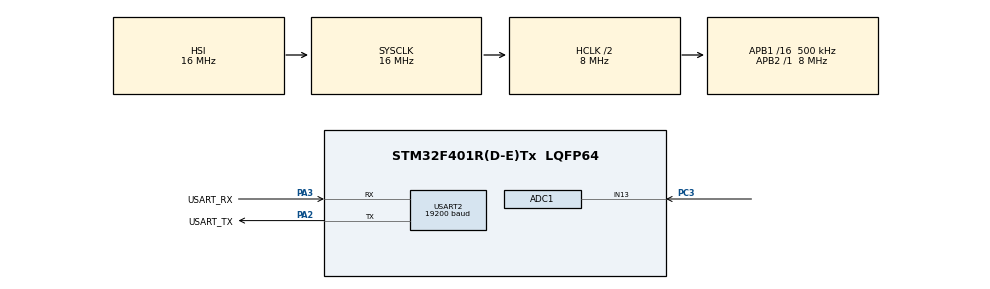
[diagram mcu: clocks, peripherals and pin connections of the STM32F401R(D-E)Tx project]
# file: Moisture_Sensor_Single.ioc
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ADC1.Channel-0\#ChannelRegularConversion=ADC_CHANNEL_13
ADC1.ClockPrescaler=ADC_CLOCK_SYNC_PCLK_DIV8
ADC1.NbrOfConversion=1
ADC1.NbrOfConversionFlag=1
ADC1.Rank-0\#ChannelRegularConversion=1
ADC1.Resolution=ADC_RESOLUTION_12B
ADC1.SamplingTime-0\#ChannelRegularConversion=ADC_SAMPLETIME_3CYCLES
ADC1.master=1
Mcu.Family=STM32F4
Mcu.Name=STM32F401R(D-E)Tx
Mcu.Package=LQFP64
NVIC.PriorityGroup=NVIC_PRIORITYGROUP_0
NVIC.RTC_WKUP_IRQn=true\:0\:0\:false\:false\:true\:true\:true\:true
PA13.GPIO_Label=TMS
PA13.Mode=Serial_Wire
PA13.Signal=SYS_JTMS-SWDIO
PA14.GPIO_Label=TCK
PA14.Mode=Serial_Wire
PA14.Signal=SYS_JTCK-SWCLK
PA2.GPIO_Label=USART_TX
PA2.GPIO_Mode=GPIO_MODE_AF_PP
PA2.GPIO_PuPd=GPIO_NOPULL
PA2.GPIO_Speed=GPIO_SPEED_FREQ_LOW
PA2.Mode=Asynchronous
PA2.Signal=USART2_TX
PA3.GPIO_Label=USART_RX
PA3.GPIO_Mode=GPIO_MODE_AF_PP
PA3.GPIO_PuPd=GPIO_NOPULL
PA3.GPIO_Speed=GPIO_SPEED_FREQ_LOW
PA3.Mode=Asynchronous
PA3.Signal=USART2_RX
PB3.GPIO_Label=SWO
PB3.Signal=SYS_JTDO-SWO
PC14-OSC32_IN.Mode=LSE-External-Oscillator
PC14-OSC32_IN.Signal=RCC_OSC32_IN
PC15-OSC32_OUT.Mode=LSE-External-Oscillator
PC15-OSC32_OUT.Signal=RCC_OSC32_OUT
PC3.Signal=ADCx_IN13
PH0\ -\ OSC_IN.Mode=HSE-External-Clock-Source
PH0\ -\ OSC_IN.Signal=RCC_OSC_IN
PH1\ -\ OSC_OUT.Mode=HSE-External-Clock-Source
PH1\ -\ OSC_OUT.Signal=RCC_OSC_OUT
ProjectManager.HeapSize=0x200
ProjectManager.StackSize=0x400
ProjectManager.TargetToolchain=STM32CubeIDE
RCC.48MHZClocksFreq_Value=18285714.285714287
RCC.AHBCLKDivider=RCC_SYSCLK_DIV2
RCC.AHBFreq_Value=8000000
RCC.APB1CLKDivider=RCC_HCLK_DIV16
RCC.APB1Freq_Value=500000
RCC.APB1TimFreq_Value=1000000
RCC.APB2Freq_Value=8000000
RCC.APB2TimFreq_Value=8000000
RCC.CortexFreq_Value=1000000
RCC.Cortex_Div=SYSTICK_CLKSOURCE_HCLK_DIV8
RCC.HCLKFreq_Value=8000000
RCC.HSE_VALUE=8000000
RCC.HSI_VALUE=16000000
RCC.PLLM=8
RCC.PLLN=64
RCC.PLLQ=7
RCC.RCC_RTC_Clock_Source_FROM_HSE=RCC_RTCCLKSOURCE_HSE_DIV31
RCC.SYSCLKFreq_VALUE=16000000
RCC.VCOOutputFreq_Value=128000000
RTC.WakeUpClock=RTC_WAKEUPCLOCK_CK_SPRE_16BITS
RTC.WakeUpCounter=4
SH.ADCx_IN13.0=ADC1_IN13,IN13
USART2.BaudRate=19200
USART2.VirtualMode=VM_ASYNC
VP_RTC_VS_RTC_Activate.Mode=RTC_Enabled
VP_RTC_VS_RTC_WakeUp_intern.Mode=WakeUp
board=NUCLEO-F401RE

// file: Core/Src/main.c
/* USER CODE BEGIN Header */
/**
  ******************************************************************************
  * @file           : main.c
  * @brief          : Main program body
  ******************************************************************************
  * @attention
  *
  * Copyright (c) 2024 STMicroelectronics.
  * All rights reserved.
  *
  * This software is licensed under terms that can be found in the LICENSE file
  * in the root directory of this software component.
  * If no LICENSE file comes with this software, it is provided AS-IS.
  *
  ******************************************************************************
  */
/* USER CODE END Header */
#include "main.h"

/* USER CODE BEGIN Includes */
#include <stdio.h>
/* USER CODE END Includes */

/* USER CODE BEGIN PD */
#define VREF 3.3
/* USER CODE END PD */

ADC_HandleTypeDef hadc1;

RTC_HandleTypeDef hrtc;

UART_HandleTypeDef huart2;

/* USER CODE BEGIN PV */
uint16_t sensor_reading = 0;
float sensor_reading_processed;
/* USER CODE END PV */

void SystemClock_Config(void);
static void MX_GPIO_Init(void);
static void MX_USART2_UART_Init(void);
static void MX_ADC1_Init(void);
static void MX_RTC_Init(void);
/* USER CODE BEGIN PFP */
int _write(int file, char *data, int len);	//For console printing
/* USER CODE END PFP */

int main(void)
{

  /* MCU Configuration--------------------------------------------------------*/

  /* Reset of all peripherals, Initializes the Flash interface and the Systick. */
  HAL_Init();

  /* Configure the system clock */
  SystemClock_Config();

  /* Initialize all configured peripherals */
  MX_GPIO_Init();
  MX_USART2_UART_Init();
  MX_ADC1_Init();
  MX_RTC_Init();

  /* Infinite loop */
  /* USER CODE BEGIN WHILE */
  while (1)
  {
	// LOW POWER MODE ENTER PROTOCOL
	//printf("Entering LOW POWER\r\n");
	HAL_SuspendTick();
    HAL_PWR_EnterSTOPMode(PWR_LOWPOWERREGULATOR_ON, PWR_STOPENTRY_WFI);
    // LOW POWER MODE EXIT PROTOCOL
	HAL_ResumeTick();
	//printf("Exiting LOW POWER\r\n");

	// SENSOR READING PROTOCOL

	// Start ADC Conversion
	HAL_ADC_Start(&hadc1);  // Start ADC conversion
	// Poll for ADC conversion completion
	if (HAL_ADC_PollForConversion(&hadc1, HAL_MAX_DELAY) == HAL_OK)
	{
		// Read ADC conversion result
		sensor_reading = HAL_ADC_GetValue(&hadc1);

		// Process the ADC value (e.g., convert to voltage or a moisture level)
		sensor_reading_processed = (sensor_reading / 4095.0) * VREF;

		// Print the ADC value and voltage
		printf("ADC Value: %d\r\n", sensor_reading);
		printf("Sensor Voltage: %.2f V\r\n", sensor_reading_processed);

		// You can add more logic to decide whether to water the plants based on the sensor data
	}

	    // Stop ADC to save power
	    HAL_ADC_Stop(&hadc1);
    /* USER CODE END WHILE */

  }
}

void SystemClock_Config(void)
{
  RCC_OscInitTypeDef RCC_OscInitStruct = {0};
  RCC_ClkInitTypeDef RCC_ClkInitStruct = {0};

  /** Configure the main internal regulator output voltage
  */
  __HAL_RCC_PWR_CLK_ENABLE();
  __HAL_PWR_VOLTAGESCALING_CONFIG(PWR_REGULATOR_VOLTAGE_SCALE2);

  /** Initializes the RCC Oscillators according to the specified parameters
  * in the RCC_OscInitTypeDef structure.
  */
  RCC_OscInitStruct.OscillatorType = RCC_OSCILLATORTYPE_HSI|RCC_OSCILLATORTYPE_LSI;
  RCC_OscInitStruct.HSIState = RCC_HSI_ON;
  RCC_OscInitStruct.HSICalibrationValue = RCC_HSICALIBRATION_DEFAULT;
  RCC_OscInitStruct.LSIState = RCC_LSI_ON;
  RCC_OscInitStruct.PLL.PLLState = RCC_PLL_NONE;
  if (HAL_RCC_OscConfig(&RCC_OscInitStruct) != HAL_OK)
  {
    Error_Handler();
  }

  /** Initializes the CPU, AHB and APB buses clocks
  */
  RCC_ClkInitStruct.ClockType = RCC_CLOCKTYPE_HCLK|RCC_CLOCKTYPE_SYSCLK
                              |RCC_CLOCKTYPE_PCLK1|RCC_CLOCKTYPE_PCLK2;
  RCC_ClkInitStruct.SYSCLKSource = RCC_SYSCLKSOURCE_HSI;
  RCC_ClkInitStruct.AHBCLKDivider = RCC_SYSCLK_DIV2;
  RCC_ClkInitStruct.APB1CLKDivider = RCC_HCLK_DIV16;
  RCC_ClkInitStruct.APB2CLKDivider = RCC_HCLK_DIV1;

  if (HAL_RCC_ClockConfig(&RCC_ClkInitStruct, FLASH_LATENCY_0) != HAL_OK)
  {
    Error_Handler();
  }
}

static void MX_ADC1_Init(void)
{

  ADC_ChannelConfTypeDef sConfig = {0};

  /** Configure the global features of the ADC (Clock, Resolution, Data Alignment and number of conversion)
  */
  hadc1.Instance = ADC1;
  hadc1.Init.ClockPrescaler = ADC_CLOCK_SYNC_PCLK_DIV8;
  hadc1.Init.Resolution = ADC_RESOLUTION_12B;
  hadc1.Init.ScanConvMode = DISABLE;
  hadc1.Init.ContinuousConvMode = DISABLE;
  hadc1.Init.DiscontinuousConvMode = DISABLE;
  hadc1.Init.ExternalTrigConvEdge = ADC_EXTERNALTRIGCONVEDGE_NONE;
  hadc1.Init.ExternalTrigConv = ADC_SOFTWARE_START;
  hadc1.Init.DataAlign = ADC_DATAALIGN_RIGHT;
  hadc1.Init.NbrOfConversion = 1;
  hadc1.Init.DMAContinuousRequests = DISABLE;
  hadc1.Init.EOCSelection = ADC_EOC_SINGLE_CONV;
  if (HAL_ADC_Init(&hadc1) != HAL_OK)
  {
    Error_Handler();
  }

  /** Configure for the selected ADC regular channel its corresponding rank in the sequencer and its sample time.
  */
  sConfig.Channel = ADC_CHANNEL_13;
  sConfig.Rank = 1;
  sConfig.SamplingTime = ADC_SAMPLETIME_3CYCLES;
  if (HAL_ADC_ConfigChannel(&hadc1, &sConfig) != HAL_OK)
  {
    Error_Handler();
  }

}

static void MX_RTC_Init(void)
{

  RTC_TimeTypeDef sTime = {0};
  RTC_DateTypeDef sDate = {0};

  /** Initialize RTC Only
  */
  hrtc.Instance = RTC;
  hrtc.Init.HourFormat = RTC_HOURFORMAT_24;
  hrtc.Init.AsynchPrediv = 127;
  hrtc.Init.SynchPrediv = 255;
  hrtc.Init.OutPut = RTC_OUTPUT_DISABLE;
  hrtc.Init.OutPutPolarity = RTC_OUTPUT_POLARITY_HIGH;
  hrtc.Init.OutPutType = RTC_OUTPUT_TYPE_OPENDRAIN;
  if (HAL_RTC_Init(&hrtc) != HAL_OK)
  {
    Error_Handler();
  }

  /** Initialize RTC and set the Time and Date
  */
  sTime.Hours = 0x0;
  sTime.Minutes = 0x0;
  sTime.Seconds = 0x0;
  sTime.DayLightSaving = RTC_DAYLIGHTSAVING_NONE;
  sTime.StoreOperation = RTC_STOREOPERATION_RESET;
  if (HAL_RTC_SetTime(&hrtc, &sTime, RTC_FORMAT_BCD) != HAL_OK)
  {
    Error_Handler();
  }
  sDate.WeekDay = RTC_WEEKDAY_MONDAY;
  sDate.Month = RTC_MONTH_JANUARY;
  sDate.Date = 0x1;
  sDate.Year = 0x0;

  if (HAL_RTC_SetDate(&hrtc, &sDate, RTC_FORMAT_BCD) != HAL_OK)
  {
    Error_Handler();
  }

  /** Enable the WakeUp
  */
  if (HAL_RTCEx_SetWakeUpTimer_IT(&hrtc, 4, RTC_WAKEUPCLOCK_CK_SPRE_16BITS) != HAL_OK)
  {
    Error_Handler();
  }

}

static void MX_USART2_UART_Init(void)
{

  huart2.Instance = USART2;
  huart2.Init.BaudRate = 19200;
  huart2.Init.WordLength = UART_WORDLENGTH_8B;
  huart2.Init.StopBits = UART_STOPBITS_1;
  huart2.Init.Parity = UART_PARITY_NONE;
  huart2.Init.Mode = UART_MODE_TX_RX;
  huart2.Init.HwFlowCtl = UART_HWCONTROL_NONE;
  huart2.Init.OverSampling = UART_OVERSAMPLING_16;
  if (HAL_UART_Init(&huart2) != HAL_OK)
  {
    Error_Handler();
  }

}

static void MX_GPIO_Init(void)
{

  /* GPIO Ports Clock Enable */
  __HAL_RCC_GPIOC_CLK_ENABLE();
  __HAL_RCC_GPIOH_CLK_ENABLE();
  __HAL_RCC_GPIOA_CLK_ENABLE();
  __HAL_RCC_GPIOB_CLK_ENABLE();

}

/* USER CODE BEGIN 4 */
int _write(int file, char *data, int len) {
    HAL_UART_Transmit(&huart2, (uint8_t*)data, len, HAL_MAX_DELAY);
    return len;
}

void HAL_RTCEx_WakeUpTimerEventCallback(RTC_HandleTypeDef *hrtc){

}
/* USER CODE END 4 */

void Error_Handler(void)
{
  __disable_irq();
  while (1)
  {
  }
}
